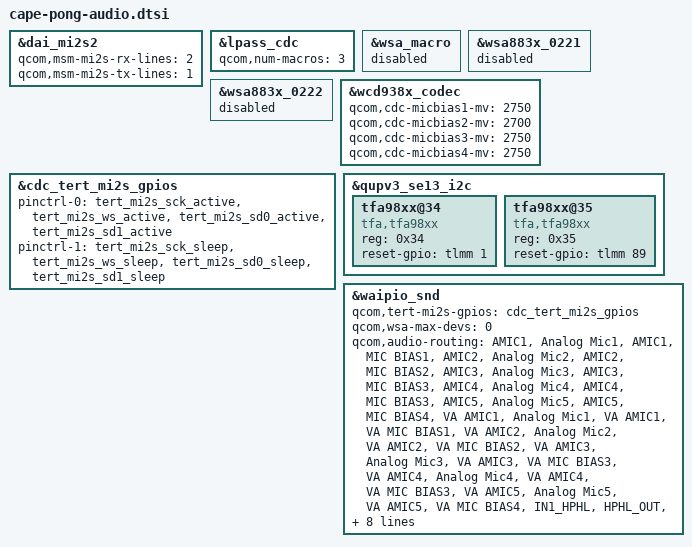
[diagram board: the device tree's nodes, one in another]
// SPDX-License-Identifier: BSD-3-Clause
// SPDX-FileCopyrightText: 2026 The PenguinOS Project

#include "waipio-audio-qrd.dtsi"

&dai_mi2s2 {
	qcom,msm-mi2s-rx-lines = <2>;
	qcom,msm-mi2s-tx-lines = <1>;
};

&lpass_cdc {
	qcom,num-macros = <3>;
};

&wsa_macro {
	status = "disabled";
};

&wsa883x_0221 {
	status = "disabled";
};

&wsa883x_0222 {
	status = "disabled";
};

&wcd938x_codec {
	qcom,cdc-micbias1-mv = <2750>;
	qcom,cdc-micbias2-mv = <2700>;
	qcom,cdc-micbias3-mv = <2750>;
	qcom,cdc-micbias4-mv = <2750>;
};

&cdc_tert_mi2s_gpios {
	pinctrl-0 = <&tert_mi2s_sck_active &tert_mi2s_ws_active
			&tert_mi2s_sd0_active &tert_mi2s_sd1_active>;
	pinctrl-1 = <&tert_mi2s_sck_sleep &tert_mi2s_ws_sleep
			&tert_mi2s_sd0_sleep &tert_mi2s_sd1_sleep>;
	status = "ok";
};

&qupv3_se13_i2c {
	status = "ok";

	tfa98xx@34 {
		compatible = "tfa,tfa98xx";
		reg = <0x34>;
		reset-gpio = <&tlmm 1 0>;	/* AUDIO_REC_PA_RST */
	};

	tfa98xx@35 {
		compatible = "tfa,tfa98xx";
		reg = <0x35>;
		reset-gpio = <&tlmm 89 0>;	/* AUDIO_SPK_PA_RST */
	};
};

&waipio_snd {
	qcom,tert-mi2s-gpios = <&cdc_tert_mi2s_gpios>;
	qcom,wsa-max-devs = <0>;

	qcom,audio-routing =
		"AMIC1", "Analog Mic1",
		"AMIC1", "MIC BIAS1",
		"AMIC2", "Analog Mic2",
		"AMIC2", "MIC BIAS2",
		"AMIC3", "Analog Mic3",
		"AMIC3", "MIC BIAS3",
		"AMIC4", "Analog Mic4",
		"AMIC4", "MIC BIAS3",
		"AMIC5", "Analog Mic5",
		"AMIC5", "MIC BIAS4",
		"VA AMIC1", "Analog Mic1",
		"VA AMIC1", "VA MIC BIAS1",
		"VA AMIC2", "Analog Mic2",
		"VA AMIC2", "VA MIC BIAS2",
		"VA AMIC3", "Analog Mic3",
		"VA AMIC3", "VA MIC BIAS3",
		"VA AMIC4", "Analog Mic4",
		"VA AMIC4", "VA MIC BIAS3",
		"VA AMIC5", "Analog Mic5",
		"VA AMIC5", "VA MIC BIAS4",
		"IN1_HPHL", "HPHL_OUT",
		"IN2_HPHR", "HPHR_OUT",
		"IN3_AUX", "AUX_OUT",
		"RX_TX DEC0_INP", "TX DEC0 MUX",
		"RX_TX DEC1_INP", "TX DEC1 MUX",
		"RX_TX DEC2_INP", "TX DEC2 MUX",
		"RX_TX DEC3_INP", "TX DEC3 MUX",
		"TX SWR_INPUT", "WCD_TX_OUTPUT",
		"VA SWR_INPUT", "VA_SWR_CLK",
		"VA SWR_INPUT", "WCD_TX_OUTPUT",
		"VA_AIF1 CAP", "VA_SWR_CLK",
		"VA_AIF2 CAP", "VA_SWR_CLK",
		"VA_AIF3 CAP", "VA_SWR_CLK";
};
